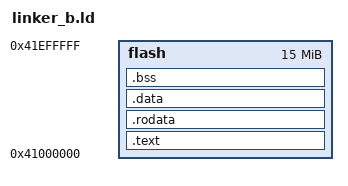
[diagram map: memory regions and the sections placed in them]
OUTPUT_FORMAT("elf32-lm32")

__DYNAMIC = 0;

MEMORY {
	flash : ORIGIN = 0x41000000, LENGTH = 0xf00000    /* 128K */
}

SECTIONS
{
	.text :
	{
		_ftext = .;
		*(.text .stub .text.* .gnu.linkonce.t.*)
		_etext = .;
	} > flash

	.rodata :
	{
		. = ALIGN(4);
		_frodata = .;
		*(.rodata .rodata.* .gnu.linkonce.r.*)
		*(.rodata1)
		_erodata = .;
	} > flash

	/* We shouldn't have a .data section, however the GNU crapchain whines if we don't */
	.data :
	{
		. = ALIGN(4);
		_fdata = .;
		*(.data .data.* .gnu.linkonce.d.*)
		*(.data1)
		_gp = ALIGN(16);
		*(.sdata .sdata.* .gnu.linkonce.s.*)
		_edata = .;
	} > flash

	.bss :
	{
		. = ALIGN(4);
		_fbss = .;
		*(.dynsbss)
		*(.sbss .sbss.* .gnu.linkonce.sb.*)
		*(.scommon)
		*(.dynbss)
		*(.bss .bss.* .gnu.linkonce.b.*)
		*(COMMON)
		. = ALIGN(4);
		_ebss = .;
		_end = .;
	} > flash
}

PROVIDE(_fstack = ORIGIN(sdram) + LENGTH(sdram) - 4);
